AUTOSAR XML (schema 00049)
package /MICROSAR/ComM_swc
  mode declaration group ComMMode: category=EXPLICIT_ORDER, initial-mode=COMM_NO_COMMUNICATION, on-transition-value=3
    mode COMM_NO_COMMUNICATION: value=0
    mode COMM_SILENT_COMMUNICATION: value=1
    mode COMM_FULL_COMMUNICATION: value=2
  data type mapping set ComMMode_DataTypeMappingSet: mode-request-type-map{implementation-data-type=ComMMode_ReferenceType, mode-group=ComMMode}  # Data Mapping for the Mode Declaration Group ComMMode.
package /MICROSAR/ComM_swc/DataTypes
  5 x impl type, all with category=TYPE_REFERENCE:
    ComM_InhibitionStatusType: range raw 0..255, implementation-data-type=uint8
    ComM_UserHandleType: range raw 0..65535, implementation-data-type=uint16
    NetworkHandleType: range raw 0..255, implementation-data-type=uint8, type-emitter=ComM
    ComMMode_ReferenceType: range raw 0..255, implementation-data-type=uint8
    ComM_ModeType: compu {0=COMM_NO_COMMUNICATION, 1=COMM_SILENT_COMMUNICATION, 2=COMM_FULL_COMMUNICATION}, range raw 0..2, implementation-data-type=uint8
package /MICROSAR/ComM_swc/Interfaces
  4 x client server interface, all with is-service=true, service-kind=COM-MANAGER:
    ComM_UserRequest
      4 x operation:
        RequestComMode: possible-error=[ComM_UserRequest/E_NOT_OK, E_MODE_LIMITATION]
          arg ComMode: type=ComM_ModeType, direction=IN
        GetRequestedComMode: possible-error=ComM_UserRequest/E_NOT_OK
          arg ComMode: type=ComM_ModeType, direction=OUT
        GetCurrentComMode: possible-error=ComM_UserRequest/E_NOT_OK
          arg ComMode: type=ComM_ModeType, direction=OUT
        GetMaxComMode: possible-error=ComM_UserRequest/E_NOT_OK
          arg ComMode: type=ComM_ModeType, direction=OUT
      4 x error:
        E_NOT_OK: error-code=1
        E_MODE_LIMITATION: error-code=2
        E_MULTIPLE_PNC_ASSIGNED: error-code=3
        E_NO_PNC_ASSIGNED: error-code=4
    ComM_ECUModeLimitation
      4 x operation, all with possible-error=ComM_ECUModeLimitation/E_NOT_OK:
        LimitECUToNoComMode
          arg Status: type=boolean, direction=IN
        ReadInhibitCounter
          arg CounterValue: type=uint16, direction=OUT
        ResetInhibitCounter
        SetECUGroupClassification
          arg Status: type=ComM_InhibitionStatusType, direction=IN
      error E_NOT_OK: error-code=1
    ComM_ChannelWakeUp
      operation PreventWakeUp: possible-error=ComM_ChannelWakeUp/E_NOT_OK
        arg Status: type=boolean, direction=IN
      operation GetInhibitionStatus: possible-error=ComM_ChannelWakeUp/E_NOT_OK
        arg Status: type=ComM_InhibitionStatusType, direction=OUT
      error E_NOT_OK: error-code=1
    ComM_ChannelLimitation
      operation LimitChannelToNoComMode: possible-error=ComM_ChannelLimitation/E_NOT_OK
        arg Status: type=boolean, direction=IN
      operation GetInhibitionStatus: possible-error=ComM_ChannelLimitation/E_NOT_OK
        arg Status: type=ComM_InhibitionStatusType, direction=OUT
      error E_NOT_OK: error-code=1
  mode switch interface ComM_CurrentMode: is-service=true, service-kind=COM-MANAGER
    mode group currentMode: type=ComMMode
package /MICROSAR/ComM_swc/ComponentTypes
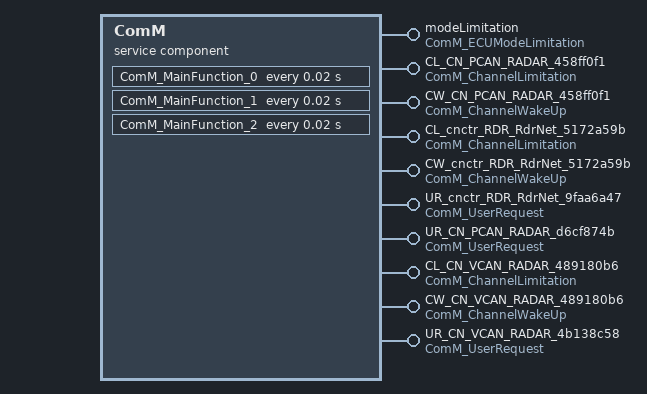
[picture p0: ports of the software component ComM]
  service sw component type ComM: category=SERVICE_COMPONENT
    10 x provide port:
      modeLimitation: provided-interface=ComM_ECUModeLimitation
      CL_CN_PCAN_RADAR_458ff0f1: provided-interface=ComM_ChannelLimitation
      CW_CN_PCAN_RADAR_458ff0f1: provided-interface=ComM_ChannelWakeUp
      CL_cnctr_RDR_RdrNet_5172a59b: provided-interface=ComM_ChannelLimitation
      CW_cnctr_RDR_RdrNet_5172a59b: provided-interface=ComM_ChannelWakeUp
      UR_cnctr_RDR_RdrNet_9faa6a47: provided-interface=ComM_UserRequest
      UR_CN_PCAN_RADAR_d6cf874b: provided-interface=ComM_UserRequest
      CL_CN_VCAN_RADAR_489180b6: provided-interface=ComM_ChannelLimitation
      CW_CN_VCAN_RADAR_489180b6: provided-interface=ComM_ChannelWakeUp
      UR_CN_VCAN_RADAR_4b138c58: provided-interface=ComM_UserRequest
    behavior ComMInternalBehavior: data-type-mapping=ComMMode_DataTypeMappingSet, handle-termination-and-restart=NO-SUPPORT, included-data-type-set=data-type=[ComMMode_ReferenceType, ComM_ModeType, ComM_InhibitionStatusType, ComM_UserHandleType, NetworkHandleType]
      timing event Timer_ComM_MainFunction_0: start-on-event=ComM_MainFunction_0, period=0.02
      4 x operation invoked event:
        OpEventLimitECUToNoComMode_LimitECUToNoComMode_modeLimitation: start-on-event=LimitECUToNoComMode, operation=modeLimitation.LimitECUToNoComMode
        OpEventReadInhibitCounter_ReadInhibitCounter_modeLimitation: start-on-event=ReadInhibitCounter, operation=modeLimitation.ReadInhibitCounter
        OpEventResetInhibitCounter_ResetInhibitCounter_modeLimitation: start-on-event=ResetInhibitCounter, operation=modeLimitation.ResetInhibitCounter
        OpEventSetECUGroupClassification_SetECUGroupClassification_modeLimitation: start-on-event=SetECUGroupClassification, operation=modeLimitation.SetECUGroupClassification
      timing event Timer_ComM_MainFunction_1: start-on-event=ComM_MainFunction_1, period=0.02
      16 x operation invoked event:
        OpEventGetInhibitionStatus_GetInhibitionStatus_CL_CN_PCAN_RADAR_458ff0f1: start-on-event=GetInhibitionStatus, operation=CL_CN_PCAN_RADAR_458ff0f1.GetInhibitionStatus
        OpEventGetInhibitionStatus_GetInhibitionStatus_CW_CN_PCAN_RADAR_458ff0f1: start-on-event=GetInhibitionStatus, operation=CW_CN_PCAN_RADAR_458ff0f1.GetInhibitionStatus
        OpEventLimitChannelToNoComMode_LimitChannelToNoComMode_CL_CN_PCAN_RADAR_458ff0f1: start-on-event=LimitChannelToNoComMode, operation=CL_CN_PCAN_RADAR_458ff0f1.LimitChannelToNoComMode
        OpEventPreventWakeUp_PreventWakeUp_CW_CN_PCAN_RADAR_458ff0f1: start-on-event=PreventWakeUp, operation=CW_CN_PCAN_RADAR_458ff0f1.PreventWakeUp
        OpEventGetInhibitionStatus_GetInhibitionStatus_CL_cnctr_RDR_RdrNet_5172a59b: start-on-event=GetInhibitionStatus, operation=CL_cnctr_RDR_RdrNet_5172a59b.GetInhibitionStatus
        OpEventGetInhibitionStatus_GetInhibitionStatus_CW_cnctr_RDR_RdrNet_5172a59b: start-on-event=GetInhibitionStatus, operation=CW_cnctr_RDR_RdrNet_5172a59b.GetInhibitionStatus
        OpEventLimitChannelToNoComMode_LimitChannelToNoComMode_CL_cnctr_RDR_RdrNet_5172a59b: start-on-event=LimitChannelToNoComMode, operation=CL_cnctr_RDR_RdrNet_5172a59b.LimitChannelToNoComMode
        OpEventPreventWakeUp_PreventWakeUp_CW_cnctr_RDR_RdrNet_5172a59b: start-on-event=PreventWakeUp, operation=CW_cnctr_RDR_RdrNet_5172a59b.PreventWakeUp
        OpEventRequestComMode_RequestComMode_UR_cnctr_RDR_RdrNet_9faa6a47: start-on-event=RequestComMode, operation=UR_cnctr_RDR_RdrNet_9faa6a47.RequestComMode
        OpEventGetRequestedComMode_GetRequestedComMode_UR_cnctr_RDR_RdrNet_9faa6a47: start-on-event=GetRequestedComMode, operation=UR_cnctr_RDR_RdrNet_9faa6a47.GetRequestedComMode
        OpEventGetCurrentComMode_GetCurrentComMode_UR_cnctr_RDR_RdrNet_9faa6a47: start-on-event=GetCurrentComMode, operation=UR_cnctr_RDR_RdrNet_9faa6a47.GetCurrentComMode
        OpEventGetMaxComMode_GetMaxComMode_UR_cnctr_RDR_RdrNet_9faa6a47: start-on-event=GetMaxComMode, operation=UR_cnctr_RDR_RdrNet_9faa6a47.GetMaxComMode
        OpEventRequestComMode_RequestComMode_UR_CN_PCAN_RADAR_d6cf874b: start-on-event=RequestComMode, operation=UR_CN_PCAN_RADAR_d6cf874b.RequestComMode
        OpEventGetRequestedComMode_GetRequestedComMode_UR_CN_PCAN_RADAR_d6cf874b: start-on-event=GetRequestedComMode, operation=UR_CN_PCAN_RADAR_d6cf874b.GetRequestedComMode
        OpEventGetCurrentComMode_GetCurrentComMode_UR_CN_PCAN_RADAR_d6cf874b: start-on-event=GetCurrentComMode, operation=UR_CN_PCAN_RADAR_d6cf874b.GetCurrentComMode
        OpEventGetMaxComMode_GetMaxComMode_UR_CN_PCAN_RADAR_d6cf874b: start-on-event=GetMaxComMode, operation=UR_CN_PCAN_RADAR_d6cf874b.GetMaxComMode
      timing event Timer_ComM_MainFunction_2: start-on-event=ComM_MainFunction_2, period=0.02
      8 x operation invoked event:
        OpEventGetInhibitionStatus_GetInhibitionStatus_CL_CN_VCAN_RADAR_489180b6: start-on-event=GetInhibitionStatus, operation=CL_CN_VCAN_RADAR_489180b6.GetInhibitionStatus
        OpEventGetInhibitionStatus_GetInhibitionStatus_CW_CN_VCAN_RADAR_489180b6: start-on-event=GetInhibitionStatus, operation=CW_CN_VCAN_RADAR_489180b6.GetInhibitionStatus
        OpEventLimitChannelToNoComMode_LimitChannelToNoComMode_CL_CN_VCAN_RADAR_489180b6: start-on-event=LimitChannelToNoComMode, operation=CL_CN_VCAN_RADAR_489180b6.LimitChannelToNoComMode
        OpEventPreventWakeUp_PreventWakeUp_CW_CN_VCAN_RADAR_489180b6: start-on-event=PreventWakeUp, operation=CW_CN_VCAN_RADAR_489180b6.PreventWakeUp
        OpEventRequestComMode_RequestComMode_UR_CN_VCAN_RADAR_4b138c58: start-on-event=RequestComMode, operation=UR_CN_VCAN_RADAR_4b138c58.RequestComMode
        OpEventGetRequestedComMode_GetRequestedComMode_UR_CN_VCAN_RADAR_4b138c58: start-on-event=GetRequestedComMode, operation=UR_CN_VCAN_RADAR_4b138c58.GetRequestedComMode
        OpEventGetCurrentComMode_GetCurrentComMode_UR_CN_VCAN_RADAR_4b138c58: start-on-event=GetCurrentComMode, operation=UR_CN_VCAN_RADAR_4b138c58.GetCurrentComMode
        OpEventGetMaxComMode_GetMaxComMode_UR_CN_VCAN_RADAR_4b138c58: start-on-event=GetMaxComMode, operation=UR_CN_VCAN_RADAR_4b138c58.GetMaxComMode
      port-api-options:
        enable-take-address=true, indirect-api=false, port=modeLimitation
        {enable-take-address=true, indirect-api=false, port-defined-argument-value{value=0, value-type=NetworkHandleType}, port=CL_cnctr_RDR_RdrNet_5172a59b}
        {enable-take-address=true, indirect-api=false, port-defined-argument-value{value=0, value-type=NetworkHandleType}, port=CW_cnctr_RDR_RdrNet_5172a59b}
        {enable-take-address=true, indirect-api=false, port-defined-argument-value{value=1, value-type=NetworkHandleType}, port=CL_CN_PCAN_RADAR_458ff0f1}
        {enable-take-address=true, indirect-api=false, port-defined-argument-value{value=1, value-type=NetworkHandleType}, port=CW_CN_PCAN_RADAR_458ff0f1}
        {enable-take-address=true, indirect-api=false, port-defined-argument-value{value=2, value-type=NetworkHandleType}, port=CL_CN_VCAN_RADAR_489180b6}
        {enable-take-address=true, indirect-api=false, port-defined-argument-value{value=2, value-type=NetworkHandleType}, port=CW_CN_VCAN_RADAR_489180b6}
        {enable-take-address=true, indirect-api=false, port-defined-argument-value{value=1, value-type=ComM_UserHandleType}, port=UR_CN_PCAN_RADAR_d6cf874b}
        {enable-take-address=true, indirect-api=false, port-defined-argument-value{value=2, value-type=ComM_UserHandleType}, port=UR_CN_VCAN_RADAR_4b138c58}
        {enable-take-address=true, indirect-api=false, port-defined-argument-value{value=0, value-type=ComM_UserHandleType}, port=UR_cnctr_RDR_RdrNet_9faa6a47}
      14 x runnable, all with can-be-invoked-concurrently=true:
        ComM_MainFunction_0
        GetInhibitionStatus: symbol=ComM_GetInhibitionStatus
        LimitECUToNoComMode: symbol=ComM_LimitECUToNoComMode
        ReadInhibitCounter: symbol=ComM_ReadInhibitCounter
        ResetInhibitCounter: symbol=ComM_ResetInhibitCounter
        SetECUGroupClassification: symbol=ComM_SetECUGroupClassification
        LimitChannelToNoComMode: symbol=ComM_LimitChannelToNoComMode
        PreventWakeUp: symbol=ComM_PreventWakeUp
        RequestComMode: symbol=ComM_RequestComMode
        GetRequestedComMode: symbol=ComM_GetRequestedComMode
        GetCurrentComMode: symbol=ComM_GetCurrentComMode
        GetMaxComMode: symbol=ComM_GetMaxComMode
        ComM_MainFunction_1
        ComM_MainFunction_2
  swc implementation ComMImplementation: programming-language=C, behavior=ComMInternalBehavior
    resource consumption ComMResourceConsumption
      5 x memory section:
        ComM_CODE: sw-addrmethod=CODE, symbol=CODE
        ComM_CONST_UNSPECIFIED: alignment=UNSPECIFIED, sw-addrmethod=CONST, symbol=CONST_UNSPECIFIED
        ComM_VAR_NOINIT_UNSPECIFIED: alignment=UNSPECIFIED, sw-addrmethod=VAR_NO_INIT, symbol=VAR_NOINIT_UNSPECIFIED
        ComM_VAR_INIT_UNSPECIFIED: alignment=UNSPECIFIED, sw-addrmethod=VAR_INIT, symbol=VAR_INIT_UNSPECIFIED
        ComM_VAR_ZERO_INIT_UNSPECIFIED: alignment=UNSPECIFIED, sw-addrmethod=VAR_CLEARED, symbol=VAR_ZERO_INIT_UNSPECIFIED
